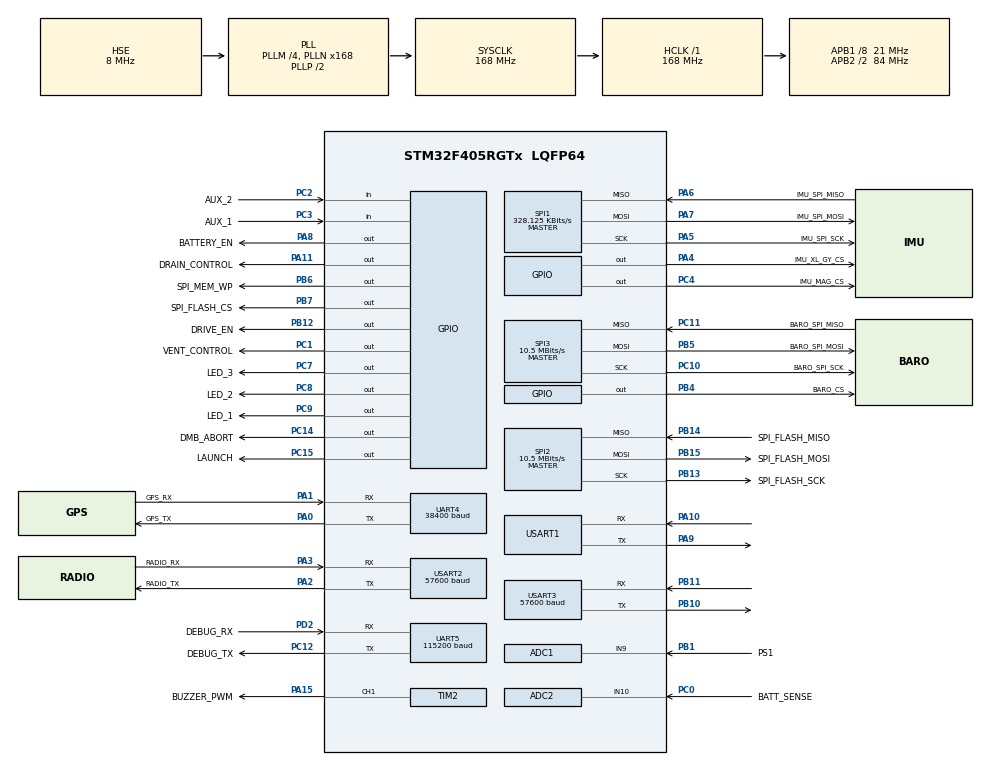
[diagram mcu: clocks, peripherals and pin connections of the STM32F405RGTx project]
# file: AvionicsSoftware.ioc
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ADC1.Channel-0\#ChannelRegularConversion=ADC_CHANNEL_9
ADC1.ContinuousConvMode=DISABLE
ADC1.NbrOfConversion=1
ADC1.NbrOfConversionFlag=1
ADC1.Rank-0\#ChannelRegularConversion=1
ADC1.SamplingTime-0\#ChannelRegularConversion=ADC_SAMPLETIME_28CYCLES
ADC1.ScanConvMode=DISABLE
ADC1.master=1
ADC2.Channel-68\#ChannelRegularConversion=ADC_CHANNEL_10
ADC2.ClockPrescaler=ADC_CLOCK_SYNC_PCLK_DIV2
ADC2.ContinuousConvMode=ENABLE
ADC2.DMAContinuousRequests=DISABLE
ADC2.DataAlign=ADC_DATAALIGN_RIGHT
ADC2.DiscontinuousConvMode=DISABLE
ADC2.EOCSelection=ADC_EOC_SEQ_CONV
ADC2.EnableAnalogWatchDog=false
ADC2.ExternalTrigConv=ADC_SOFTWARE_START
ADC2.ExternalTrigConvEdge=ADC_EXTERNALTRIGCONVEDGE_NONE
ADC2.InjNumberOfConversion=0
ADC2.NbrOfConversion=1
ADC2.NbrOfConversionFlag=1
ADC2.Rank-68\#ChannelRegularConversion=1
ADC2.Resolution=ADC_RESOLUTION_12B
ADC2.SamplingTime-68\#ChannelRegularConversion=ADC_SAMPLETIME_480CYCLES
ADC2.ScanConvMode=DISABLE
Dma.Request0=UART4_RX
Dma.UART4_RX.0.Direction=DMA_PERIPH_TO_MEMORY
Dma.UART4_RX.0.FIFOMode=DMA_FIFOMODE_DISABLE
Dma.UART4_RX.0.Instance=DMA1_Stream2
Dma.UART4_RX.0.MemDataAlignment=DMA_MDATAALIGN_BYTE
Dma.UART4_RX.0.MemInc=DMA_MINC_ENABLE
Dma.UART4_RX.0.Mode=DMA_NORMAL
Dma.UART4_RX.0.PeriphDataAlignment=DMA_PDATAALIGN_BYTE
Dma.UART4_RX.0.PeriphInc=DMA_PINC_DISABLE
Dma.UART4_RX.0.Priority=DMA_PRIORITY_LOW
FREERTOS.INCLUDE_vTaskDelayUntil=1
FREERTOS.Tasks01=defaultTask,0,128,StartDefaultTask,Default,NULL
FREERTOS.configMAX_TASK_NAME_LEN=64
FREERTOS.configTOTAL_HEAP_SIZE=98304
FREERTOS.configUSE_NEWLIB_REENTRANT=1
FREERTOS.configUSE_TIMERS=1
IWDG.Prescaler=IWDG_PRESCALER_16
IWDG.Reload=624
Mcu.Family=STM32F4
Mcu.Name=STM32F405RGTx
Mcu.Package=LQFP64
NVIC.DMA1_Stream2_IRQn=true\:5\:0\:false\:false\:true\:true\:false\:true\:true
NVIC.PriorityGroup=NVIC_PRIORITYGROUP_4
NVIC.TIM1_UP_TIM10_IRQn=true\:15\:0\:false\:false\:true\:false\:false\:true\:true
NVIC.TimeBase=TIM1_UP_TIM10_IRQn
NVIC.TimeBaseIP=TIM1
NVIC.UART4_IRQn=true\:5\:0\:false\:false\:true\:true\:true\:true\:true
NVIC.UART5_IRQn=true\:5\:0\:false\:false\:true\:true\:true\:true\:true
NVIC.USART1_IRQn=true\:5\:0\:false\:false\:true\:true\:true\:true\:true
NVIC.USART2_IRQn=true\:5\:0\:false\:false\:true\:true\:true\:true\:true
NVIC.USART3_IRQn=true\:5\:0\:false\:false\:true\:true\:true\:true\:true
PA0-WKUP.GPIO_Label=GPS_TX
PA0-WKUP.Mode=Asynchronous
PA0-WKUP.Signal=UART4_TX
PA1.GPIO_Label=GPS_RX
PA1.Mode=Asynchronous
PA1.Signal=UART4_RX
PA10.Mode=Asynchronous
PA10.Signal=USART1_RX
PA11.GPIO_Label=DRAIN_CONTROL
PA11.Signal=GPIO_Output
PA13.Mode=Trace_Asynchronous_SW
PA13.Signal=SYS_JTMS-SWDIO
PA14.Mode=Trace_Asynchronous_SW
PA14.Signal=SYS_JTCK-SWCLK
PA15.GPIO_Label=BUZZER_PWM
PA15.Signal=S_TIM2_CH1_ETR
PA2.GPIO_Label=RADIO_TX
PA2.Mode=Asynchronous
PA2.Signal=USART2_TX
PA3.GPIO_Label=RADIO_RX
PA3.Mode=Asynchronous
PA3.Signal=USART2_RX
PA4.GPIO_Label=IMU_XL_GY_CS
PA4.Signal=GPIO_Output
PA5.GPIO_Label=IMU_SPI_SCK
PA5.Mode=Full_Duplex_Master
PA5.Signal=SPI1_SCK
PA6.GPIO_Label=IMU_SPI_MISO
PA6.Mode=Full_Duplex_Master
PA6.Signal=SPI1_MISO
PA7.GPIO_Label=IMU_SPI_MOSI
PA7.Mode=Full_Duplex_Master
PA7.Signal=SPI1_MOSI
PA8.GPIO_Label=BATTERY_EN
PA8.GPIO_PuPd=GPIO_PULLDOWN
PA8.PinState=GPIO_PIN_RESET
PA8.Signal=GPIO_Output
PA9.Mode=Asynchronous
PA9.Signal=USART1_TX
PB1.GPIO_Label=PS1
PB1.Signal=ADCx_IN9
PB10.Mode=Asynchronous
PB10.Signal=USART3_TX
PB11.Mode=Asynchronous
PB11.Signal=USART3_RX
PB12.GPIO_Label=DRIVE_EN
PB12.Signal=GPIO_Output
PB13.GPIO_Label=SPI_FLASH_SCK
PB13.Mode=Full_Duplex_Master
PB13.Signal=SPI2_SCK
PB14.GPIO_Label=SPI_FLASH_MISO
PB14.Mode=Full_Duplex_Master
PB14.Signal=SPI2_MISO
PB15.GPIO_Label=SPI_FLASH_MOSI
PB15.Mode=Full_Duplex_Master
PB15.Signal=SPI2_MOSI
PB3.Mode=Trace_Asynchronous_SW
PB3.Signal=SYS_JTDO-SWO
PB4.GPIO_Label=BARO_CS
PB4.Signal=GPIO_Output
PB5.GPIO_Label=BARO_SPI_MOSI
PB5.Mode=Full_Duplex_Master
PB5.Signal=SPI3_MOSI
PB6.GPIO_Label=SPI_MEM_WP
PB6.Signal=GPIO_Output
PB7.GPIO_Label=SPI_FLASH_CS
PB7.Signal=GPIO_Output
PC0.GPIO_Label=BATT_SENSE
PC0.Signal=ADCx_IN10
PC1.GPIO_Label=VENT_CONTROL
PC1.Signal=GPIO_Output
PC10.GPIO_Label=BARO_SPI_SCK
PC10.Mode=Full_Duplex_Master
PC10.Signal=SPI3_SCK
PC11.GPIO_Label=BARO_SPI_MISO
PC11.Mode=Full_Duplex_Master
PC11.Signal=SPI3_MISO
PC12.GPIO_Label=DEBUG_TX
PC12.Mode=Asynchronous
PC12.Signal=UART5_TX
PC14-OSC32_IN.GPIO_Label=DMB_ABORT
PC14-OSC32_IN.GPIO_PuPd=GPIO_PULLDOWN
PC14-OSC32_IN.Signal=GPIO_Output
PC15-OSC32_OUT.GPIO_Label=LAUNCH
PC15-OSC32_OUT.GPIO_PuPd=GPIO_PULLDOWN
PC15-OSC32_OUT.Signal=GPIO_Output
PC2.GPIO_Label=AUX_2
PC2.GPIO_PuPd=GPIO_PULLUP
PC2.Signal=GPIO_Input
PC3.GPIO_Label=AUX_1
PC3.GPIO_PuPd=GPIO_PULLUP
PC3.Signal=GPIO_Input
PC4.GPIO_Label=IMU_MAG_CS
PC4.Signal=GPIO_Output
PC7.GPIO_Label=LED_3
PC7.Signal=GPIO_Output
PC8.GPIO_Label=LED_2
PC8.Signal=GPIO_Output
PC9.GPIO_Label=LED_1
PC9.Signal=GPIO_Output
PD2.GPIO_Label=DEBUG_RX
PD2.Mode=Asynchronous
PD2.Signal=UART5_RX
PH0-OSC_IN.Mode=HSE-External-Clock-Source
PH0-OSC_IN.Signal=RCC_OSC_IN
PH1-OSC_OUT.Mode=HSE-External-Clock-Source
PH1-OSC_OUT.Signal=RCC_OSC_OUT
ProjectManager.HeapSize=0x200
ProjectManager.StackSize=0x400
ProjectManager.TargetToolchain=STM32CubeIDE
RCC.48MHZClocksFreq_Value=84000000
RCC.AHBFreq_Value=168000000
RCC.APB1CLKDivider=RCC_HCLK_DIV8
RCC.APB1Freq_Value=21000000
RCC.APB1TimFreq_Value=42000000
RCC.APB2CLKDivider=RCC_HCLK_DIV2
RCC.APB2Freq_Value=84000000
RCC.APB2TimFreq_Value=168000000
RCC.CortexFreq_Value=168000000
RCC.HCLKFreq_Value=168000000
RCC.HSE_VALUE=8000000
RCC.HSI_VALUE=16000000
RCC.LSE_VALUE=32768
RCC.PLLM=4
RCC.PLLN=168
RCC.PLLSourceVirtual=RCC_PLLSOURCE_HSE
RCC.SYSCLKFreq_VALUE=168000000
RCC.SYSCLKSource=RCC_SYSCLKSOURCE_PLLCLK
RCC.VCOOutputFreq_Value=336000000
SH.ADCx_IN10.0=ADC2_IN10,IN10
SH.ADCx_IN9.0=ADC1_IN9,IN9
SH.S_TIM2_CH1_ETR.0=TIM2_CH1,PWM Generation1 CH1
SPI1.BaudRatePrescaler=SPI_BAUDRATEPRESCALER_256
SPI1.CLKPhase=SPI_PHASE_2EDGE
SPI1.CLKPolarity=SPI_POLARITY_HIGH
SPI1.CalculateBaudRate=328.125 KBits/s
SPI1.Direction=SPI_DIRECTION_2LINES
SPI1.Mode=SPI_MODE_MASTER
SPI1.VirtualType=VM_MASTER
SPI2.CalculateBaudRate=10.5 MBits/s
SPI2.Direction=SPI_DIRECTION_2LINES
SPI2.Mode=SPI_MODE_MASTER
SPI2.VirtualType=VM_MASTER
SPI3.BaudRatePrescaler=SPI_BAUDRATEPRESCALER_2
SPI3.CalculateBaudRate=10.5 MBits/s
SPI3.Direction=SPI_DIRECTION_2LINES
SPI3.Mode=SPI_MODE_MASTER
SPI3.VirtualType=VM_MASTER
TIM2.AutoReloadPreload=TIM_AUTORELOAD_PRELOAD_ENABLE
TIM2.Channel-PWM\ Generation1\ CH1=TIM_CHANNEL_1
TIM2.ClockDivision=TIM_CLOCKDIVISION_DIV1
TIM2.Period=210-1
TIM2.Prescaler=952-1
TIM2.Pulse-PWM\ Generation1\ CH1=50
UART4.BaudRate=38400
UART4.VirtualMode=Asynchronous
UART5.BaudRate=115200
UART5.VirtualMode=Asynchronous
USART1.VirtualMode=VM_ASYNC
USART2.BaudRate=57600
USART2.VirtualMode=VM_ASYNC
USART3.BaudRate=57600
USART3.VirtualMode=VM_ASYNC
VP_CRC_VS_CRC.Mode=CRC_Activate
VP_FREERTOS_VS_CMSIS_V1.Mode=CMSIS_V1
VP_IWDG_VS_IWDG.Mode=IWDG_Activate
VP_SYS_VS_tim1.Mode=TIM1
VP_TIM2_VS_ClockSourceINT.Mode=Internal
board=VanderAvionics

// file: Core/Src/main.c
/* USER CODE BEGIN Header */
/**
  ******************************************************************************
  * @file           : main.c
  * @brief          : Main program body
  ******************************************************************************
  * @attention
  *
  * Copyright (c) 2022 STMicroelectronics.
  * All rights reserved.
  *
  * This software is licensed under terms that can be found in the LICENSE file
  * in the root directory of this software component.
  * If no LICENSE file comes with this software, it is provided AS-IS.
  *
  ******************************************************************************
  */
/* USER CODE END Header */
#include "main.h"
#include "cmsis_os.h"

/* USER CODE BEGIN Includes */
#include "RunInterface.hpp"

//#include "GPIO.hpp"
/* USER CODE END Includes */

ADC_HandleTypeDef hadc1;
ADC_HandleTypeDef hadc2;

CRC_HandleTypeDef hcrc;

IWDG_HandleTypeDef hiwdg;

SPI_HandleTypeDef hspi1;
SPI_HandleTypeDef hspi2;
SPI_HandleTypeDef hspi3;

TIM_HandleTypeDef htim2;

UART_HandleTypeDef huart4;
DMA_HandleTypeDef hdma_uart4_rx;

osThreadId defaultTaskHandle;

void SystemClock_Config(void);
static void MX_GPIO_Init(void);
static void MX_DMA_Init(void);
static void MX_SPI1_Init(void);
static void MX_USART2_UART_Init(void);
static void MX_UART4_Init(void);
static void MX_CRC_Init(void);
static void MX_SPI3_Init(void);
static void MX_UART5_Init(void);
static void MX_ADC2_Init(void);
static void MX_SPI2_Init(void);
static void MX_TIM2_Init(void);
static void MX_USART1_UART_Init(void);
static void MX_USART3_UART_Init(void);
static void MX_ADC1_Init(void);
//static void MX_IWDG_Init(void);
void StartDefaultTask(void const * argument);

int main(void)
{

  /* MCU Configuration--------------------------------------------------------*/

  /* Reset of all peripherals, Initializes the Flash interface and the Systick. */
  HAL_Init();

  /* Configure the system clock */
  SystemClock_Config();

  /* Initialize all configured peripherals */
  MX_GPIO_Init();
  MX_DMA_Init();
  MX_SPI1_Init();
  MX_USART2_UART_Init();
  MX_UART4_Init();
  MX_CRC_Init();
  MX_SPI3_Init();
  MX_UART5_Init();
  MX_ADC2_Init();
  MX_SPI2_Init();
  MX_TIM2_Init();
  MX_USART1_UART_Init();
  MX_USART3_UART_Init();
  MX_ADC1_Init();
  //MX_IWDG_Init();
  //WDGTask::Inst().InitIWDG();

  /* USER CODE BEGIN 2 */

  run_interface();

#if 0

  /* USER CODE END 2 */

  /* Create the thread(s) */
  /* definition and creation of defaultTask */
  osThreadDef(defaultTask, StartDefaultTask, osPriorityNormal, 0, 128);
  defaultTaskHandle = osThreadCreate(osThread(defaultTask), NULL);

  /* Start scheduler */
  osKernelStart();

  /* We should never get here as control is now taken by the scheduler */
  /* Infinite loop */
  while (1)
  {

    /* USER CODE BEGIN 3 */
  }
#endif
  /* USER CODE END 3 */
}

void SystemClock_Config(void)
{
  RCC_OscInitTypeDef RCC_OscInitStruct = {0};
  RCC_ClkInitTypeDef RCC_ClkInitStruct = {0};

  /** Configure the main internal regulator output voltage
  */
  __HAL_RCC_PWR_CLK_ENABLE();
  __HAL_PWR_VOLTAGESCALING_CONFIG(PWR_REGULATOR_VOLTAGE_SCALE1);

  /** Initializes the RCC Oscillators according to the specified parameters
  * in the RCC_OscInitTypeDef structure.
  */
  RCC_OscInitStruct.OscillatorType = RCC_OSCILLATORTYPE_LSI|RCC_OSCILLATORTYPE_HSE;
  RCC_OscInitStruct.HSEState = RCC_HSE_BYPASS;
  RCC_OscInitStruct.LSIState = RCC_LSI_ON;
  RCC_OscInitStruct.PLL.PLLState = RCC_PLL_ON;
  RCC_OscInitStruct.PLL.PLLSource = RCC_PLLSOURCE_HSE;
  RCC_OscInitStruct.PLL.PLLM = 4;
  RCC_OscInitStruct.PLL.PLLN = 168;
  RCC_OscInitStruct.PLL.PLLP = RCC_PLLP_DIV2;
  RCC_OscInitStruct.PLL.PLLQ = 4;
  if (HAL_RCC_OscConfig(&RCC_OscInitStruct) != HAL_OK)
  {
    Error_Handler();
  }

  /** Initializes the CPU, AHB and APB buses clocks
  */
  RCC_ClkInitStruct.ClockType = RCC_CLOCKTYPE_HCLK|RCC_CLOCKTYPE_SYSCLK
                              |RCC_CLOCKTYPE_PCLK1|RCC_CLOCKTYPE_PCLK2;
  RCC_ClkInitStruct.SYSCLKSource = RCC_SYSCLKSOURCE_PLLCLK;
  RCC_ClkInitStruct.AHBCLKDivider = RCC_SYSCLK_DIV1;
  RCC_ClkInitStruct.APB1CLKDivider = RCC_HCLK_DIV8;
  RCC_ClkInitStruct.APB2CLKDivider = RCC_HCLK_DIV2;

  if (HAL_RCC_ClockConfig(&RCC_ClkInitStruct, FLASH_LATENCY_5) != HAL_OK)
  {
    Error_Handler();
  }
}

static void MX_ADC1_Init(void)
{

  ADC_ChannelConfTypeDef sConfig = {0};

  /** Configure the global features of the ADC (Clock, Resolution, Data Alignment and number of conversion)
  */
  hadc1.Instance = ADC1;
  hadc1.Init.ClockPrescaler = ADC_CLOCK_SYNC_PCLK_DIV4;
  hadc1.Init.Resolution = ADC_RESOLUTION_12B;
  hadc1.Init.ScanConvMode = DISABLE;
  hadc1.Init.ContinuousConvMode = DISABLE;
  hadc1.Init.DiscontinuousConvMode = DISABLE;
  hadc1.Init.ExternalTrigConvEdge = ADC_EXTERNALTRIGCONVEDGE_NONE;
  hadc1.Init.ExternalTrigConv = ADC_SOFTWARE_START;
  hadc1.Init.DataAlign = ADC_DATAALIGN_RIGHT;
  hadc1.Init.NbrOfConversion = 1;
  hadc1.Init.DMAContinuousRequests = DISABLE;
  hadc1.Init.EOCSelection = ADC_EOC_SINGLE_CONV;
  if (HAL_ADC_Init(&hadc1) != HAL_OK)
  {
    Error_Handler();
  }

  /** Configure for the selected ADC regular channel its corresponding rank in the sequencer and its sample time.
  */
  sConfig.Channel = ADC_CHANNEL_9;
  sConfig.Rank = 1;
  sConfig.SamplingTime = ADC_SAMPLETIME_28CYCLES;
  if (HAL_ADC_ConfigChannel(&hadc1, &sConfig) != HAL_OK)
  {
    Error_Handler();
  }

}

static void MX_ADC2_Init(void)
{

  ADC_ChannelConfTypeDef sConfig = {0};

  /** Configure the global features of the ADC (Clock, Resolution, Data Alignment and number of conversion)
  */
  hadc2.Instance = ADC2;
  hadc2.Init.ClockPrescaler = ADC_CLOCK_SYNC_PCLK_DIV2;
  hadc2.Init.Resolution = ADC_RESOLUTION_12B;
  hadc2.Init.ScanConvMode = DISABLE;
  hadc2.Init.ContinuousConvMode = ENABLE;
  hadc2.Init.DiscontinuousConvMode = DISABLE;
  hadc2.Init.ExternalTrigConvEdge = ADC_EXTERNALTRIGCONVEDGE_NONE;
  hadc2.Init.ExternalTrigConv = ADC_SOFTWARE_START;
  hadc2.Init.DataAlign = ADC_DATAALIGN_RIGHT;
  hadc2.Init.NbrOfConversion = 1;
  hadc2.Init.DMAContinuousRequests = DISABLE;
  hadc2.Init.EOCSelection = ADC_EOC_SEQ_CONV;
  if (HAL_ADC_Init(&hadc2) != HAL_OK)
  {
    Error_Handler();
  }

  /** Configure for the selected ADC regular channel its corresponding rank in the sequencer and its sample time.
  */
  sConfig.Channel = ADC_CHANNEL_10;
  sConfig.Rank = 1;
  sConfig.SamplingTime = ADC_SAMPLETIME_480CYCLES;
  if (HAL_ADC_ConfigChannel(&hadc2, &sConfig) != HAL_OK)
  {
    Error_Handler();
  }

}

static void MX_CRC_Init(void)
{

  hcrc.Instance = CRC;
  if (HAL_CRC_Init(&hcrc) != HAL_OK)
  {
    Error_Handler();
  }

}

//static void MX_IWDG_Init(void)
//{
//
//  /* USER CODE BEGIN IWDG_Init 0 */
//
//  /* USER CODE END IWDG_Init 0 */
//
//  /* USER CODE BEGIN IWDG_Init 1 */
//
//  /* USER CODE END IWDG_Init 1 */
//  hiwdg.Instance = IWDG;
//  hiwdg.Init.Prescaler = IWDG_PRESCALER_64;
//  hiwdg.Init.Reload = 2499;		//624
//
//  if (HAL_IWDG_Init(&hiwdg) != HAL_OK)
//  {
//    Error_Handler();
//  }
//  /* USER CODE BEGIN IWDG_Init 2 */
//
//  /* USER CODE END IWDG_Init 2 */
//
//}

static void MX_SPI1_Init(void)
{

  /* SPI1 parameter configuration*/
  hspi1.Instance = SPI1;
  hspi1.Init.Mode = SPI_MODE_MASTER;
  hspi1.Init.Direction = SPI_DIRECTION_2LINES;
  hspi1.Init.DataSize = SPI_DATASIZE_8BIT;
  hspi1.Init.CLKPolarity = SPI_POLARITY_HIGH;
  hspi1.Init.CLKPhase = SPI_PHASE_2EDGE;
  hspi1.Init.NSS = SPI_NSS_SOFT;
  hspi1.Init.BaudRatePrescaler = SPI_BAUDRATEPRESCALER_256;
  hspi1.Init.FirstBit = SPI_FIRSTBIT_MSB;
  hspi1.Init.TIMode = SPI_TIMODE_DISABLE;
  hspi1.Init.CRCCalculation = SPI_CRCCALCULATION_DISABLE;
  hspi1.Init.CRCPolynomial = 10;
  if (HAL_SPI_Init(&hspi1) != HAL_OK)
  {
    Error_Handler();
  }

}

static void MX_SPI2_Init(void)
{

  /* SPI2 parameter configuration*/
  hspi2.Instance = SPI2;
  hspi2.Init.Mode = SPI_MODE_MASTER;
  hspi2.Init.Direction = SPI_DIRECTION_2LINES;
  hspi2.Init.DataSize = SPI_DATASIZE_8BIT;
  hspi2.Init.CLKPolarity = SPI_POLARITY_LOW;
  hspi2.Init.CLKPhase = SPI_PHASE_1EDGE;
  hspi2.Init.NSS = SPI_NSS_SOFT;
  hspi2.Init.BaudRatePrescaler = SPI_BAUDRATEPRESCALER_2;
  hspi2.Init.FirstBit = SPI_FIRSTBIT_MSB;
  hspi2.Init.TIMode = SPI_TIMODE_DISABLE;
  hspi2.Init.CRCCalculation = SPI_CRCCALCULATION_DISABLE;
  hspi2.Init.CRCPolynomial = 10;
  if (HAL_SPI_Init(&hspi2) != HAL_OK)
  {
    Error_Handler();
  }

}

static void MX_SPI3_Init(void)
{

  /* SPI3 parameter configuration*/
  hspi3.Instance = SPI3;
  hspi3.Init.Mode = SPI_MODE_MASTER;
  hspi3.Init.Direction = SPI_DIRECTION_2LINES;
  hspi3.Init.DataSize = SPI_DATASIZE_8BIT;
  hspi3.Init.CLKPolarity = SPI_POLARITY_LOW;
  hspi3.Init.CLKPhase = SPI_PHASE_1EDGE;
  hspi3.Init.NSS = SPI_NSS_SOFT;
  hspi3.Init.BaudRatePrescaler = SPI_BAUDRATEPRESCALER_2;
  hspi3.Init.FirstBit = SPI_FIRSTBIT_MSB;
  hspi3.Init.TIMode = SPI_TIMODE_DISABLE;
  hspi3.Init.CRCCalculation = SPI_CRCCALCULATION_DISABLE;
  hspi3.Init.CRCPolynomial = 10;
  if (HAL_SPI_Init(&hspi3) != HAL_OK)
  {
    Error_Handler();
  }

}

static void MX_TIM2_Init(void)
{

  TIM_ClockConfigTypeDef sClockSourceConfig = {0};
  TIM_MasterConfigTypeDef sMasterConfig = {0};
  TIM_OC_InitTypeDef sConfigOC = {0};

  htim2.Instance = TIM2;
  htim2.Init.Prescaler = 952-1;
  htim2.Init.CounterMode = TIM_COUNTERMODE_UP;
  htim2.Init.Period = 210-1;
  htim2.Init.ClockDivision = TIM_CLOCKDIVISION_DIV1;
  htim2.Init.AutoReloadPreload = TIM_AUTORELOAD_PRELOAD_ENABLE;
  if (HAL_TIM_Base_Init(&htim2) != HAL_OK)
  {
    Error_Handler();
  }
  sClockSourceConfig.ClockSource = TIM_CLOCKSOURCE_INTERNAL;
  if (HAL_TIM_ConfigClockSource(&htim2, &sClockSourceConfig) != HAL_OK)
  {
    Error_Handler();
  }
  if (HAL_TIM_PWM_Init(&htim2) != HAL_OK)
  {
    Error_Handler();
  }
  sMasterConfig.MasterOutputTrigger = TIM_TRGO_RESET;
  sMasterConfig.MasterSlaveMode = TIM_MASTERSLAVEMODE_DISABLE;
  if (HAL_TIMEx_MasterConfigSynchronization(&htim2, &sMasterConfig) != HAL_OK)
  {
    Error_Handler();
  }
  sConfigOC.OCMode = TIM_OCMODE_PWM1;
  sConfigOC.Pulse = 50;
  sConfigOC.OCPolarity = TIM_OCPOLARITY_HIGH;
  sConfigOC.OCFastMode = TIM_OCFAST_DISABLE;
  if (HAL_TIM_PWM_ConfigChannel(&htim2, &sConfigOC, TIM_CHANNEL_1) != HAL_OK)
  {
    Error_Handler();
  }
  HAL_TIM_MspPostInit(&htim2);

}

static void MX_UART4_Init(void)
{

  huart4.Instance = UART4;
  huart4.Init.BaudRate = 38400;
  huart4.Init.WordLength = UART_WORDLENGTH_8B;
  huart4.Init.StopBits = UART_STOPBITS_1;
  huart4.Init.Parity = UART_PARITY_NONE;
  huart4.Init.Mode = UART_MODE_TX_RX;
  huart4.Init.HwFlowCtl = UART_HWCONTROL_NONE;
  huart4.Init.OverSampling = UART_OVERSAMPLING_16;
  if (HAL_UART_Init(&huart4) != HAL_OK)
  {
    Error_Handler();
  }

}

static void MX_UART5_Init(void)
{

  LL_USART_InitTypeDef USART_InitStruct = {0};

  LL_GPIO_InitTypeDef GPIO_InitStruct = {0};

  /* Peripheral clock enable */
  LL_APB1_GRP1_EnableClock(LL_APB1_GRP1_PERIPH_UART5);

  LL_AHB1_GRP1_EnableClock(LL_AHB1_GRP1_PERIPH_GPIOC);
  LL_AHB1_GRP1_EnableClock(LL_AHB1_GRP1_PERIPH_GPIOD);
  /**UART5 GPIO Configuration
  PC12   ------> UART5_TX
  PD2   ------> UART5_RX
  */
  GPIO_InitStruct.Pin = LL_GPIO_PIN_12;
  GPIO_InitStruct.Mode = LL_GPIO_MODE_ALTERNATE;
  GPIO_InitStruct.Speed = LL_GPIO_SPEED_FREQ_VERY_HIGH;
  GPIO_InitStruct.OutputType = LL_GPIO_OUTPUT_PUSHPULL;
  GPIO_InitStruct.Pull = LL_GPIO_PULL_NO;
  GPIO_InitStruct.Alternate = LL_GPIO_AF_8;
  LL_GPIO_Init(GPIOC, &GPIO_InitStruct);

  GPIO_InitStruct.Pin = LL_GPIO_PIN_2;
  GPIO_InitStruct.Mode = LL_GPIO_MODE_ALTERNATE;
  GPIO_InitStruct.Speed = LL_GPIO_SPEED_FREQ_VERY_HIGH;
  GPIO_InitStruct.OutputType = LL_GPIO_OUTPUT_PUSHPULL;
  GPIO_InitStruct.Pull = LL_GPIO_PULL_NO;
  GPIO_InitStruct.Alternate = LL_GPIO_AF_8;
  LL_GPIO_Init(GPIOD, &GPIO_InitStruct);

  /* UART5 interrupt Init */
  NVIC_SetPriority(UART5_IRQn, NVIC_EncodePriority(NVIC_GetPriorityGrouping(),5, 0));
  NVIC_EnableIRQ(UART5_IRQn);

  USART_InitStruct.BaudRate = 115200;
  USART_InitStruct.DataWidth = LL_USART_DATAWIDTH_8B;
  USART_InitStruct.StopBits = LL_USART_STOPBITS_1;
  USART_InitStruct.Parity = LL_USART_PARITY_NONE;
  USART_InitStruct.TransferDirection = LL_USART_DIRECTION_TX_RX;
  USART_InitStruct.HardwareFlowControl = LL_USART_HWCONTROL_NONE;
  USART_InitStruct.OverSampling = LL_USART_OVERSAMPLING_16;
  LL_USART_Init(UART5, &USART_InitStruct);
  LL_USART_ConfigAsyncMode(UART5);
  LL_USART_Enable(UART5);

}

static void MX_USART1_UART_Init(void)
{

  LL_USART_InitTypeDef USART_InitStruct = {0};

  LL_GPIO_InitTypeDef GPIO_InitStruct = {0};

  /* Peripheral clock enable */
  LL_APB2_GRP1_EnableClock(LL_APB2_GRP1_PERIPH_USART1);

  LL_AHB1_GRP1_EnableClock(LL_AHB1_GRP1_PERIPH_GPIOA);
  /**USART1 GPIO Configuration
  PA9   ------> USART1_TX
  PA10   ------> USART1_RX
  */
  GPIO_InitStruct.Pin = LL_GPIO_PIN_9|LL_GPIO_PIN_10;
  GPIO_InitStruct.Mode = LL_GPIO_MODE_ALTERNATE;
  GPIO_InitStruct.Speed = LL_GPIO_SPEED_FREQ_VERY_HIGH;
  GPIO_InitStruct.OutputType = LL_GPIO_OUTPUT_PUSHPULL;
  GPIO_InitStruct.Pull = LL_GPIO_PULL_NO;
  GPIO_InitStruct.Alternate = LL_GPIO_AF_7;
  LL_GPIO_Init(GPIOA, &GPIO_InitStruct);

  /* USART1 interrupt Init */
  NVIC_SetPriority(USART1_IRQn, NVIC_EncodePriority(NVIC_GetPriorityGrouping(),5, 0));
  NVIC_EnableIRQ(USART1_IRQn);

  USART_InitStruct.BaudRate = 115200;
  USART_InitStruct.DataWidth = LL_USART_DATAWIDTH_8B;
  USART_InitStruct.StopBits = LL_USART_STOPBITS_1;
  USART_InitStruct.Parity = LL_USART_PARITY_NONE;
  USART_InitStruct.TransferDirection = LL_USART_DIRECTION_TX_RX;
  USART_InitStruct.HardwareFlowControl = LL_USART_HWCONTROL_NONE;
  USART_InitStruct.OverSampling = LL_USART_OVERSAMPLING_16;
  LL_USART_Init(USART1, &USART_InitStruct);
  LL_USART_ConfigAsyncMode(USART1);
  LL_USART_Enable(USART1);

}

static void MX_USART2_UART_Init(void)
{

  LL_USART_InitTypeDef USART_InitStruct = {0};

  LL_GPIO_InitTypeDef GPIO_InitStruct = {0};

  /* Peripheral clock enable */
  LL_APB1_GRP1_EnableClock(LL_APB1_GRP1_PERIPH_USART2);

  LL_AHB1_GRP1_EnableClock(LL_AHB1_GRP1_PERIPH_GPIOA);
  /**USART2 GPIO Configuration
  PA2   ------> USART2_TX
  PA3   ------> USART2_RX
  */
  GPIO_InitStruct.Pin = LL_GPIO_PIN_2|LL_GPIO_PIN_3;
  GPIO_InitStruct.Mode = LL_GPIO_MODE_ALTERNATE;
  GPIO_InitStruct.Speed = LL_GPIO_SPEED_FREQ_VERY_HIGH;
  GPIO_InitStruct.OutputType = LL_GPIO_OUTPUT_PUSHPULL;
  GPIO_InitStruct.Pull = LL_GPIO_PULL_NO;
  GPIO_InitStruct.Alternate = LL_GPIO_AF_7;
  LL_GPIO_Init(GPIOA, &GPIO_InitStruct);

  /* USART2 interrupt Init */
  NVIC_SetPriority(USART2_IRQn, NVIC_EncodePriority(NVIC_GetPriorityGrouping(),5, 0));
  NVIC_EnableIRQ(USART2_IRQn);

  USART_InitStruct.BaudRate = 57600;
  USART_InitStruct.DataWidth = LL_USART_DATAWIDTH_8B;
  USART_InitStruct.StopBits = LL_USART_STOPBITS_1;
  USART_InitStruct.Parity = LL_USART_PARITY_NONE;
  USART_InitStruct.TransferDirection = LL_USART_DIRECTION_TX_RX;
  USART_InitStruct.HardwareFlowControl = LL_USART_HWCONTROL_NONE;
  USART_InitStruct.OverSampling = LL_USART_OVERSAMPLING_16;
  LL_USART_Init(USART2, &USART_InitStruct);
  LL_USART_ConfigAsyncMode(USART2);
  LL_USART_Enable(USART2);

}

static void MX_USART3_UART_Init(void)
{

  LL_USART_InitTypeDef USART_InitStruct = {0};

  LL_GPIO_InitTypeDef GPIO_InitStruct = {0};

  /* Peripheral clock enable */
  LL_APB1_GRP1_EnableClock(LL_APB1_GRP1_PERIPH_USART3);

  LL_AHB1_GRP1_EnableClock(LL_AHB1_GRP1_PERIPH_GPIOB);
  /**USART3 GPIO Configuration
  PB10   ------> USART3_TX
  PB11   ------> USART3_RX
  */
  GPIO_InitStruct.Pin = LL_GPIO_PIN_10|LL_GPIO_PIN_11;
  GPIO_InitStruct.Mode = LL_GPIO_MODE_ALTERNATE;
  GPIO_InitStruct.Speed = LL_GPIO_SPEED_FREQ_VERY_HIGH;
  GPIO_InitStruct.OutputType = LL_GPIO_OUTPUT_PUSHPULL;
  GPIO_InitStruct.Pull = LL_GPIO_PULL_NO;
  GPIO_InitStruct.Alternate = LL_GPIO_AF_7;
  LL_GPIO_Init(GPIOB, &GPIO_InitStruct);

  /* USART3 interrupt Init */
  NVIC_SetPriority(USART3_IRQn, NVIC_EncodePriority(NVIC_GetPriorityGrouping(),5, 0));
  NVIC_EnableIRQ(USART3_IRQn);

  USART_InitStruct.BaudRate = 57600;
  USART_InitStruct.DataWidth = LL_USART_DATAWIDTH_8B;
  USART_InitStruct.StopBits = LL_USART_STOPBITS_1;
  USART_InitStruct.Parity = LL_USART_PARITY_NONE;
  USART_InitStruct.TransferDirection = LL_USART_DIRECTION_TX_RX;
  USART_InitStruct.HardwareFlowControl = LL_USART_HWCONTROL_NONE;
  USART_InitStruct.OverSampling = LL_USART_OVERSAMPLING_16;
  LL_USART_Init(USART3, &USART_InitStruct);
  LL_USART_ConfigAsyncMode(USART3);
  LL_USART_Enable(USART3);

}

static void MX_DMA_Init(void)
{

  /* DMA controller clock enable */
  __HAL_RCC_DMA1_CLK_ENABLE();

  /* DMA interrupt init */
  /* DMA1_Stream2_IRQn interrupt configuration */
  HAL_NVIC_SetPriority(DMA1_Stream2_IRQn, 5, 0);
  HAL_NVIC_EnableIRQ(DMA1_Stream2_IRQn);

}

static void MX_GPIO_Init(void)
{
  GPIO_InitTypeDef GPIO_InitStruct = {0};

  /* GPIO Ports Clock Enable */
  __HAL_RCC_GPIOC_CLK_ENABLE();
  __HAL_RCC_GPIOH_CLK_ENABLE();
  __HAL_RCC_GPIOA_CLK_ENABLE();
  __HAL_RCC_GPIOB_CLK_ENABLE();
  __HAL_RCC_GPIOD_CLK_ENABLE();

  /*Configure GPIO pin Output Level */
  HAL_GPIO_WritePin(GPIOC, DMB_ABORT_Pin|LAUNCH_Pin|VENT_CONTROL_Pin|IMU_MAG_CS_Pin
                          |LED_3_Pin|LED_2_Pin|LED_1_Pin, GPIO_PIN_RESET);

  /*Configure GPIO pin Output Level */
  HAL_GPIO_WritePin(GPIOA, IMU_XL_GY_CS_Pin|BATTERY_EN_Pin|DRAIN_CONTROL_Pin, GPIO_PIN_RESET);

  /*Configure GPIO pin Output Level */
  HAL_GPIO_WritePin(GPIOB, DRIVE_EN_Pin|BARO_CS_Pin|SPI_MEM_WP_Pin|SPI_FLASH_CS_Pin, GPIO_PIN_RESET);

  /*Configure GPIO pins : PC13 PC5 PC6 */
  GPIO_InitStruct.Pin = GPIO_PIN_13|GPIO_PIN_5|GPIO_PIN_6;
  GPIO_InitStruct.Mode = GPIO_MODE_ANALOG;
  GPIO_InitStruct.Pull = GPIO_NOPULL;
  HAL_GPIO_Init(GPIOC, &GPIO_InitStruct);

  /*Configure GPIO pins : DMB_ABORT_Pin LAUNCH_Pin */
  GPIO_InitStruct.Pin = DMB_ABORT_Pin|LAUNCH_Pin;
  GPIO_InitStruct.Mode = GPIO_MODE_OUTPUT_PP;
  GPIO_InitStruct.Pull = GPIO_PULLDOWN;
  GPIO_InitStruct.Speed = GPIO_SPEED_FREQ_LOW;
  HAL_GPIO_Init(GPIOC, &GPIO_InitStruct);

  /*Configure GPIO pins : VENT_CONTROL_Pin IMU_MAG_CS_Pin LED_3_Pin LED_2_Pin
                           LED_1_Pin */
  GPIO_InitStruct.Pin = VENT_CONTROL_Pin|IMU_MAG_CS_Pin|LED_3_Pin|LED_2_Pin
                          |LED_1_Pin;
  GPIO_InitStruct.Mode = GPIO_MODE_OUTPUT_PP;
  GPIO_InitStruct.Pull = GPIO_NOPULL;
  GPIO_InitStruct.Speed = GPIO_SPEED_FREQ_LOW;
  HAL_GPIO_Init(GPIOC, &GPIO_InitStruct);

  /*Configure GPIO pins : AUX_2_Pin AUX_1_Pin */
  GPIO_InitStruct.Pin = AUX_2_Pin|AUX_1_Pin;
  GPIO_InitStruct.Mode = GPIO_MODE_INPUT;
  GPIO_InitStruct.Pull = GPIO_PULLUP;
  HAL_GPIO_Init(GPIOC, &GPIO_InitStruct);

  /*Configure GPIO pins : IMU_XL_GY_CS_Pin DRAIN_CONTROL_Pin */
  GPIO_InitStruct.Pin = IMU_XL_GY_CS_Pin|DRAIN_CONTROL_Pin;
  GPIO_InitStruct.Mode = GPIO_MODE_OUTPUT_PP;
  GPIO_InitStruct.Pull = GPIO_NOPULL;
  GPIO_InitStruct.Speed = GPIO_SPEED_FREQ_LOW;
  HAL_GPIO_Init(GPIOA, &GPIO_InitStruct);

  /*Configure GPIO pins : PB0 PB2 PB8 PB9 */
  GPIO_InitStruct.Pin = GPIO_PIN_0|GPIO_PIN_2|GPIO_PIN_8|GPIO_PIN_9;
  GPIO_InitStruct.Mode = GPIO_MODE_ANALOG;
  GPIO_InitStruct.Pull = GPIO_NOPULL;
  HAL_GPIO_Init(GPIOB, &GPIO_InitStruct);

  /*Configure GPIO pins : DRIVE_EN_Pin BARO_CS_Pin SPI_MEM_WP_Pin SPI_FLASH_CS_Pin */
  GPIO_InitStruct.Pin = DRIVE_EN_Pin|BARO_CS_Pin|SPI_MEM_WP_Pin|SPI_FLASH_CS_Pin;
  GPIO_InitStruct.Mode = GPIO_MODE_OUTPUT_PP;
  GPIO_InitStruct.Pull = GPIO_NOPULL;
  GPIO_InitStruct.Speed = GPIO_SPEED_FREQ_LOW;
  HAL_GPIO_Init(GPIOB, &GPIO_InitStruct);

  /*Configure GPIO pin : BATTERY_EN_Pin */
  GPIO_InitStruct.Pin = BATTERY_EN_Pin;
  GPIO_InitStruct.Mode = GPIO_MODE_OUTPUT_PP;
  GPIO_InitStruct.Pull = GPIO_PULLDOWN;
  GPIO_InitStruct.Speed = GPIO_SPEED_FREQ_LOW;
  HAL_GPIO_Init(BATTERY_EN_GPIO_Port, &GPIO_InitStruct);

  /*Configure GPIO pin : PA12 */
  GPIO_InitStruct.Pin = GPIO_PIN_12;
  GPIO_InitStruct.Mode = GPIO_MODE_ANALOG;
  GPIO_InitStruct.Pull = GPIO_NOPULL;
  HAL_GPIO_Init(GPIOA, &GPIO_InitStruct);

}

void StartDefaultTask(void const * argument)
{
}

void HAL_TIM_PeriodElapsedCallback(TIM_HandleTypeDef *htim)
{
  if (htim->Instance == TIM1) {
    HAL_IncTick();
  }
}

void Error_Handler(void)
{
  /* USER CODE BEGIN Error_Handler_Debug */
  /* User can add his own implementation to report the HAL error return state */
  //
  while (1)
  {
	  if (HAL_IWDG_Init(&hiwdg) != HAL_OK)
	    {
		  __disable_irq();
		  HAL_NVIC_SystemReset();
	    }
  }
  /* USER CODE END Error_Handler_Debug */
}
